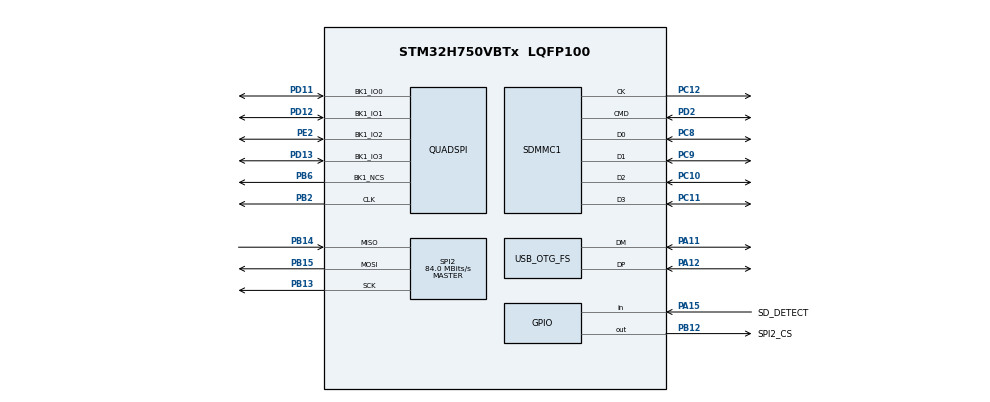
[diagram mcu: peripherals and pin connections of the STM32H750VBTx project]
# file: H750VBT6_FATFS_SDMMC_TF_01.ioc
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CORTEX_M7.AccessPermission-Cortex_Memory_Protection_Unit_Region0_Settings=MPU_REGION_FULL_ACCESS
CORTEX_M7.AccessPermission-Cortex_Memory_Protection_Unit_Region1_Settings=MPU_REGION_FULL_ACCESS
CORTEX_M7.AccessPermission-Cortex_Memory_Protection_Unit_Region2_Settings=MPU_REGION_FULL_ACCESS
CORTEX_M7.AccessPermission-Cortex_Memory_Protection_Unit_Region3_Settings=MPU_REGION_FULL_ACCESS
CORTEX_M7.AccessPermission-Cortex_Memory_Protection_Unit_Region4_Settings=MPU_REGION_FULL_ACCESS
CORTEX_M7.AccessPermission-Cortex_Memory_Protection_Unit_Region5_Settings=MPU_REGION_FULL_ACCESS
CORTEX_M7.AccessPermission-Cortex_Memory_Protection_Unit_Region6_Settings=MPU_REGION_FULL_ACCESS
CORTEX_M7.BaseAddress-Cortex_Memory_Protection_Unit_Region0_Settings=0x24000000
CORTEX_M7.BaseAddress-Cortex_Memory_Protection_Unit_Region1_Settings=0x60000000
CORTEX_M7.BaseAddress-Cortex_Memory_Protection_Unit_Region2_Settings=0x30000000
CORTEX_M7.BaseAddress-Cortex_Memory_Protection_Unit_Region3_Settings=0x30020000
CORTEX_M7.BaseAddress-Cortex_Memory_Protection_Unit_Region4_Settings=0x30040000
CORTEX_M7.BaseAddress-Cortex_Memory_Protection_Unit_Region5_Settings=0x38000000
CORTEX_M7.BaseAddress-Cortex_Memory_Protection_Unit_Region6_Settings=0x90000000
CORTEX_M7.CPU_DCache=Enabled
CORTEX_M7.CPU_ICache=Enabled
CORTEX_M7.Enable-Cortex_Memory_Protection_Unit_Region0_Settings=MPU_REGION_ENABLE
CORTEX_M7.Enable-Cortex_Memory_Protection_Unit_Region1_Settings=MPU_REGION_ENABLE
CORTEX_M7.Enable-Cortex_Memory_Protection_Unit_Region2_Settings=MPU_REGION_ENABLE
CORTEX_M7.Enable-Cortex_Memory_Protection_Unit_Region3_Settings=MPU_REGION_ENABLE
CORTEX_M7.Enable-Cortex_Memory_Protection_Unit_Region4_Settings=MPU_REGION_ENABLE
CORTEX_M7.Enable-Cortex_Memory_Protection_Unit_Region5_Settings=MPU_REGION_ENABLE
CORTEX_M7.Enable-Cortex_Memory_Protection_Unit_Region6_Settings=MPU_REGION_ENABLE
CORTEX_M7.IsBufferable-Cortex_Memory_Protection_Unit_Region0_Settings=MPU_ACCESS_BUFFERABLE
CORTEX_M7.IsBufferable-Cortex_Memory_Protection_Unit_Region1_Settings=MPU_ACCESS_BUFFERABLE
CORTEX_M7.IsBufferable-Cortex_Memory_Protection_Unit_Region6_Settings=MPU_ACCESS_BUFFERABLE
CORTEX_M7.IsCacheable-Cortex_Memory_Protection_Unit_Region0_Settings=MPU_ACCESS_CACHEABLE
CORTEX_M7.IsCacheable-Cortex_Memory_Protection_Unit_Region2_Settings=MPU_ACCESS_NOT_CACHEABLE
CORTEX_M7.IsCacheable-Cortex_Memory_Protection_Unit_Region3_Settings=MPU_ACCESS_NOT_CACHEABLE
CORTEX_M7.IsCacheable-Cortex_Memory_Protection_Unit_Region4_Settings=MPU_ACCESS_NOT_CACHEABLE
CORTEX_M7.IsCacheable-Cortex_Memory_Protection_Unit_Region5_Settings=MPU_ACCESS_CACHEABLE
CORTEX_M7.IsCacheable-Cortex_Memory_Protection_Unit_Region6_Settings=MPU_ACCESS_CACHEABLE
CORTEX_M7.MPU_Control=MPU_PRIVILEGED_DEFAULT
CORTEX_M7.Size-Cortex_Memory_Protection_Unit_Region0_Settings=MPU_REGION_SIZE_512KB
CORTEX_M7.Size-Cortex_Memory_Protection_Unit_Region1_Settings=MPU_REGION_SIZE_256MB
CORTEX_M7.Size-Cortex_Memory_Protection_Unit_Region2_Settings=MPU_REGION_SIZE_128KB
CORTEX_M7.Size-Cortex_Memory_Protection_Unit_Region3_Settings=MPU_REGION_SIZE_128KB
CORTEX_M7.Size-Cortex_Memory_Protection_Unit_Region4_Settings=MPU_REGION_SIZE_32KB
CORTEX_M7.Size-Cortex_Memory_Protection_Unit_Region5_Settings=MPU_REGION_SIZE_64KB
CORTEX_M7.Size-Cortex_Memory_Protection_Unit_Region6_Settings=MPU_REGION_SIZE_8MB
CORTEX_M7.TypeExtField-Cortex_Memory_Protection_Unit_Region0_Settings=MPU_TEX_LEVEL1
CORTEX_M7.TypeExtField-Cortex_Memory_Protection_Unit_Region6_Settings=MPU_TEX_LEVEL1
Dma.Request0=SPI2_RX
Dma.Request1=SPI2_TX
Dma.SPI2_RX.0.Direction=DMA_PERIPH_TO_MEMORY
Dma.SPI2_RX.0.EventEnable=DISABLE
Dma.SPI2_RX.0.FIFOMode=DMA_FIFOMODE_DISABLE
Dma.SPI2_RX.0.Instance=DMA1_Stream0
Dma.SPI2_RX.0.MemDataAlignment=DMA_MDATAALIGN_BYTE
Dma.SPI2_RX.0.MemInc=DMA_MINC_ENABLE
Dma.SPI2_RX.0.Mode=DMA_NORMAL
Dma.SPI2_RX.0.PeriphDataAlignment=DMA_PDATAALIGN_BYTE
Dma.SPI2_RX.0.PeriphInc=DMA_PINC_DISABLE
Dma.SPI2_RX.0.Polarity=HAL_DMAMUX_REQ_GEN_RISING
Dma.SPI2_RX.0.Priority=DMA_PRIORITY_VERY_HIGH
Dma.SPI2_RX.0.RequestNumber=1
Dma.SPI2_RX.0.SignalID=NONE
Dma.SPI2_RX.0.SyncEnable=DISABLE
Dma.SPI2_RX.0.SyncPolarity=HAL_DMAMUX_SYNC_NO_EVENT
Dma.SPI2_RX.0.SyncRequestNumber=1
Dma.SPI2_RX.0.SyncSignalID=NONE
Dma.SPI2_TX.1.Direction=DMA_MEMORY_TO_PERIPH
Dma.SPI2_TX.1.EventEnable=DISABLE
Dma.SPI2_TX.1.FIFOMode=DMA_FIFOMODE_DISABLE
Dma.SPI2_TX.1.Instance=DMA1_Stream1
Dma.SPI2_TX.1.MemDataAlignment=DMA_MDATAALIGN_BYTE
Dma.SPI2_TX.1.MemInc=DMA_MINC_ENABLE
Dma.SPI2_TX.1.Mode=DMA_NORMAL
Dma.SPI2_TX.1.PeriphDataAlignment=DMA_PDATAALIGN_BYTE
Dma.SPI2_TX.1.PeriphInc=DMA_PINC_DISABLE
Dma.SPI2_TX.1.Polarity=HAL_DMAMUX_REQ_GEN_RISING
Dma.SPI2_TX.1.Priority=DMA_PRIORITY_VERY_HIGH
Dma.SPI2_TX.1.RequestNumber=1
Dma.SPI2_TX.1.SignalID=NONE
Dma.SPI2_TX.1.SyncEnable=DISABLE
Dma.SPI2_TX.1.SyncPolarity=HAL_DMAMUX_SYNC_NO_EVENT
Dma.SPI2_TX.1.SyncRequestNumber=1
Dma.SPI2_TX.1.SyncSignalID=NONE
FATFS.BSP.number=1
FATFS._CODE_PAGE=936
FATFS._USE_LFN=2
FATFS._USE_MUTEX=0
FATFS0.BSP.STBoard=false
FATFS0.BSP.api=Unknown
FATFS0.BSP.instance=PA15 (JTDI)
FATFS0.BSP.ip=GPIO
FATFS0.BSP.mode=Input
FATFS0.BSP.name=Detect_SDIO
FATFS0.BSP.solution=PA15 (JTDI)
FREERTOS.INCLUDE_vTaskDelayUntil=1
FREERTOS.Tasks01=defaultTask,24,512,StartDefaultTask,Default,NULL,Dynamic,NULL,NULL
FREERTOS.configGENERATE_RUN_TIME_STATS=1
FREERTOS.configMAX_TASK_NAME_LEN=32
FREERTOS.configTOTAL_HEAP_SIZE=131072
FREERTOS.configUSE_NEWLIB_REENTRANT=1
FREERTOS.configUSE_STATS_FORMATTING_FUNCTIONS=1
FREERTOS.copyHeapFile=0
Mcu.Family=STM32H7
Mcu.Name=STM32H750VBTx
Mcu.Package=LQFP100
Mcu.UserConstants=QSPI_FLASH_SIZE_2N_OFFSET,0
NVIC.DMA1_Stream0_IRQn=true\:5\:0\:false\:false\:true\:true\:false\:true\:true
NVIC.DMA1_Stream1_IRQn=true\:5\:0\:false\:false\:true\:true\:false\:true\:true
NVIC.OTG_FS_IRQn=true\:5\:0\:false\:false\:true\:true\:false\:true\:true
NVIC.PriorityGroup=NVIC_PRIORITYGROUP_4
NVIC.SDMMC1_IRQn=true\:5\:0\:false\:false\:true\:true\:true\:true\:true
NVIC.SPI2_IRQn=true\:5\:0\:false\:false\:true\:true\:false\:true\:true
NVIC.TIM3_IRQn=true\:14\:0\:true\:false\:true\:true\:true\:true\:true
NVIC.TIM6_DAC_IRQn=true\:15\:0\:true\:false\:true\:false\:true\:true\:true
NVIC.TIM7_IRQn=true\:0\:0\:true\:false\:true\:false\:true\:true\:true
NVIC.TimeBase=TIM6_DAC_IRQn
NVIC.TimeBaseIP=TIM6
PA11.GPIO_Speed=GPIO_SPEED_FREQ_VERY_HIGH
PA11.Mode=Device_Only
PA11.Signal=USB_OTG_FS_DM
PA12.GPIO_Speed=GPIO_SPEED_FREQ_VERY_HIGH
PA12.Mode=Device_Only
PA12.Signal=USB_OTG_FS_DP
PA13\ (JTMS/SWDIO).Mode=Serial_Wire
PA13\ (JTMS/SWDIO).Signal=DEBUG_JTMS-SWDIO
PA14\ (JTCK/SWCLK).Mode=Serial_Wire
PA14\ (JTCK/SWCLK).Signal=DEBUG_JTCK-SWCLK
PA15\ (JTDI).GPIO_Label=SD_DETECT
PA15\ (JTDI).Signal=GPIO_Input
PB12.GPIO_Label=SPI2_CS
PB12.GPIO_ModeDefaultOutputPP=GPIO_MODE_OUTPUT_OD
PB12.GPIO_PuPd=GPIO_NOPULL
PB12.GPIO_Speed=GPIO_SPEED_FREQ_VERY_HIGH
PB12.PinState=GPIO_PIN_SET
PB12.Signal=GPIO_Output
PB13.GPIO_Speed=GPIO_SPEED_FREQ_VERY_HIGH
PB13.Mode=Full_Duplex_Master
PB13.Signal=SPI2_SCK
PB14.GPIO_Speed=GPIO_SPEED_FREQ_VERY_HIGH
PB14.Mode=Full_Duplex_Master
PB14.Signal=SPI2_MISO
PB15.GPIO_Speed=GPIO_SPEED_FREQ_VERY_HIGH
PB15.Mode=Full_Duplex_Master
PB15.Signal=SPI2_MOSI
PB2.Mode=Single Bank 1
PB2.Signal=QUADSPI_CLK
PB6.Mode=Single Bank 1
PB6.Signal=QUADSPI_BK1_NCS
PC10.Mode=SD_4_bits_Wide_bus
PC10.Signal=SDMMC1_D2
PC11.Mode=SD_4_bits_Wide_bus
PC11.Signal=SDMMC1_D3
PC12.Mode=SD_4_bits_Wide_bus
PC12.Signal=SDMMC1_CK
PC8.Mode=SD_4_bits_Wide_bus
PC8.Signal=SDMMC1_D0
PC9.Mode=SD_4_bits_Wide_bus
PC9.Signal=SDMMC1_D1
PD11.Mode=Single Bank 1
PD11.Signal=QUADSPI_BK1_IO0
PD12.Mode=Single Bank 1
PD12.Signal=QUADSPI_BK1_IO1
PD13.Mode=Single Bank 1
PD13.Signal=QUADSPI_BK1_IO3
PD2.Mode=SD_4_bits_Wide_bus
PD2.Signal=SDMMC1_CMD
PE2.Mode=Single Bank 1
PE2.Signal=QUADSPI_BK1_IO2
PH0-OSC_IN\ (PH0).Mode=HSE-External-Oscillator
PH0-OSC_IN\ (PH0).Signal=RCC_OSC_IN
PH1-OSC_OUT\ (PH1).Mode=HSE-External-Oscillator
PH1-OSC_OUT\ (PH1).Signal=RCC_OSC_OUT
ProjectManager.HeapSize=0x1000
ProjectManager.StackSize=0x1000
ProjectManager.TargetToolchain=STM32CubeIDE
QUADSPI.ChipSelectHighTime=QSPI_CS_HIGH_TIME_2_CYCLE
QUADSPI.ClockPrescaler=1
QUADSPI.FifoThreshold=32
QUADSPI.FlashSize=QSPI_FLASH_SIZE_2N_OFFSET
QUADSPI.SampleShifting=QSPI_SAMPLE_SHIFTING_HALFCYCLE
RCC.ADCFreq_Value=168000000
RCC.APB1Freq_Value=100000000
RCC.APB2Freq_Value=100000000
RCC.APB3Freq_Value=100000000
RCC.APB4Freq_Value=100000000
RCC.CECCLockSelection=RCC_CECCLKSOURCE_LSI
RCC.CKPERSourceSelection=RCC_CLKPSOURCE_HSE
RCC.CSI_VALUE=4000000
RCC.CortexFreq_Value=400000000
RCC.Cortex_Div=SYSTICK_CLKSOURCE_HCLK
RCC.Cortex_DivARG=SystemCoreClock/1000
RCC.D1PPRE=RCC_APB3_DIV2
RCC.D2PPRE1=RCC_APB1_DIV2
RCC.D2PPRE2=RCC_APB2_DIV2
RCC.D3PPRE=RCC_APB4_DIV2
RCC.DFSDMCLockSelection=RCC_DFSDM1CLKSOURCE_D2PCLK1
RCC.DIVM1=5
RCC.DIVM2=25
RCC.DIVM3=25
RCC.DIVN1=160
RCC.DIVN2=504
RCC.DIVN3=160
RCC.DIVP1=2
RCC.DIVP2=3
RCC.DIVP3=2
RCC.DIVQ1=4
RCC.DIVQ2=2
RCC.DIVR1=2
RCC.DIVR2=2
RCC.DIVR3=25
RCC.DSICLockSelection=RCC_DSICLKSOURCE_PHY
RCC.DSIPHY_Div=8
RCC.DSITX_Div=4
RCC.DSI_PHY_VALUE=12288000
RCC.EXTERNAL_CLOCK_VALUE=12288000
RCC.FDCANCLockSelection=RCC_FDCANCLKSOURCE_PLL
RCC.FMCCLockSelection=RCC_FMCCLKSOURCE_D1HCLK
RCC.HCLKFreq_Value=200000000
RCC.HPRE=RCC_HCLK_DIV2
RCC.HSE_VALUE=25000000
RCC.HSIDiv=RCC_PLLSAIDIVR_1
RCC.HSI_VALUE=64000000
RCC.I2C123CLockSelection=RCC_I2C123CLKSOURCE_D2PCLK1
RCC.I2C4CLockSelection=RCC_I2C4CLKSOURCE_D3PCLK1
RCC.LPTIM1CLockSelection=RCC_LPTIM1CLKSOURCE_PLL3
RCC.LPTIM2CLockSelection=RCC_LPTIM2CLKSOURCE_D3PCLK1
RCC.LPTIM345CLockSelection=RCC_LPTIM345CLKSOURCE_PLL3
RCC.LPUART1CLockSelection=RCC_LPUART1CLKSOURCE_D3PCLK1
RCC.PLL1_VCI_Range-AdvancedSettings=RCC_PLL1VCIRANGE_0
RCC.PLL1_VCO_SEL-AdvancedSettings=RCC_PLL1VCOWIDE
RCC.PLLDSIDev=2
RCC.PLLDSIIDF=DSI_PLL_IN_DIV1
RCC.PLLDSIMult=2
RCC.PLLDSINDIV=20
RCC.PLLDSIODF=DSI_PLL_OUT_DIV1
RCC.PLLSourceVirtual=RCC_PLLSOURCE_HSE
RCC.RC48_VALUE=48000000
RCC.RCC_MCO1Source=RCC_MCO1SOURCE_HSI
RCC.RCC_MCO2Source=RCC_MCO2SOURCE_SYSCLK
RCC.RCC_MCODiv1=RCC_MCODIV_1
RCC.RCC_MCODiv2=RCC_MCODIV_1
RCC.RCC_RTC_Clock_Source_FROM_HSE=RCC_RTCCLKSOURCE_HSE_DIV2
RCC.RNGCLockSelection=RCC_RNGCLKSOURCE_HSI48
RCC.SAI1CLockSelection=RCC_SAI1CLKSOURCE_PLL
RCC.SAI23CLockSelection=RCC_SAI23CLKSOURCE_PLL
RCC.SAI4ACLockSelection=RCC_SAI4ACLKSOURCE_PLL
RCC.SAI4BCLockSelection=RCC_SAI4BCLKSOURCE_PLL
RCC.SPDIFCLockSelection=RCC_SPDIFRXCLKSOURCE_PLL
RCC.SPI123CLockSelection=RCC_SPI123CLKSOURCE_PLL2
RCC.SPI6CLockSelection=RCC_SPI6CLKSOURCE_D3PCLK1
RCC.SWPCLockSelection=RCC_SWPMI1CLKSOURCE_D2PCLK1
RCC.SYSCLKFreq_VALUE=400000000
RCC.SYSCLKSource=RCC_SYSCLKSOURCE_PLLCLK
RCC.Spi45ClockSelection=RCC_SPI45CLKSOURCE_D2PCLK1
RCC.USART16CLockSelection=RCC_USART16CLKSOURCE_D2PCLK2
RCC.USART234578CLockSelection=RCC_USART234578CLKSOURCE_D2PCLK1
RCC.USBCLockSelection=RCC_USBCLKSOURCE_HSI48
RCC.USBFreq_Value=48000000
SDMMC1.ClockDiv=4
SPI2.BaudRatePrescaler=SPI_BAUDRATEPRESCALER_2
SPI2.CalculateBaudRate=84.0 MBits/s
SPI2.DataSize=SPI_DATASIZE_8BIT
SPI2.Direction=SPI_DIRECTION_2LINES
SPI2.Mode=SPI_MODE_MASTER
SPI2.VirtualType=VM_MASTER
TIM3.AutoReloadPreload=TIM_AUTORELOAD_PRELOAD_ENABLE
TIM3.Channel-Output\ Compare1\ No\ Output=TIM_CHANNEL_1
TIM3.Channel-Output\ Compare2\ No\ Output=TIM_CHANNEL_2
TIM3.Channel-Output\ Compare3\ No\ Output=TIM_CHANNEL_3
TIM3.Channel-Output\ Compare4\ No\ Output=TIM_CHANNEL_4
TIM3.OC1Preload=DISABLE
TIM3.OCMode_1=TIM_OCMODE_TOGGLE
TIM3.OCMode_2=TIM_OCMODE_TIMING
TIM3.OCMode_3=TIM_OCMODE_TIMING
TIM3.OCMode_4=TIM_OCMODE_TIMING
TIM7.AutoReloadPreload=TIM_AUTORELOAD_PRELOAD_DISABLE
TIM7.Period=50- 1
TIM7.Prescaler=200 - 1
USB_DEVICE.APP_RX_DATA_SIZE-CDC_FS=2048
USB_DEVICE.APP_TX_DATA_SIZE-CDC_FS=2048
USB_DEVICE.CLASS_NAME_FS=CDC
USB_DEVICE.VirtualMode-CDC_FS=Cdc
USB_DEVICE.VirtualModeFS=Cdc_FS
USB_OTG_FS.VirtualMode=Device_Only
VP_FATFS_VS_SDIO.Mode=SDIO
VP_FREERTOS_VS_CMSIS_V2.Mode=CMSIS_V2
VP_SYS_VS_tim6.Mode=TIM6
VP_TIM3_VS_no_output1.Mode=Output Compare1 No Output
VP_TIM3_VS_no_output2.Mode=Output Compare2 No Output
VP_TIM3_VS_no_output3.Mode=Output Compare3 No Output
VP_TIM3_VS_no_output4.Mode=Output Compare4 No Output
VP_TIM7_VS_ClockSourceINT.Mode=Enable_Timer
VP_USB_DEVICE_VS_USB_DEVICE_CDC_FS.Mode=CDC_FS
board=custom

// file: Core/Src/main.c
/* USER CODE BEGIN Header */
/**
  ******************************************************************************
  * @file           : main.c
  * @brief          : Main program body
  ******************************************************************************
  * @attention
  *
  * <h2><center>&copy; Copyright (c) 2022 STMicroelectronics.
  * All rights reserved.</center></h2>
  *
  * This software component is licensed by ST under BSD 3-Clause license,
  * the "License"; You may not use this file except in compliance with the
  * License. You may obtain a copy of the License at:
  *                        opensource.org/licenses/BSD-3-Clause
  *
  ******************************************************************************
  */
/* USER CODE END Header */
#include "main.h"
#include "cmsis_os.h"
#include "dma.h"
#include "fatfs.h"
#include "sdmmc.h"
#include "spi.h"
#include "tim.h"
#include "usb_device.h"
#include "gpio.h"

/* USER CODE BEGIN Includes */
#include "usbd_cdc_if.h"
/* USER CODE END Includes */

void SystemClock_Config(void);
static void MPU_Config(void);
void MX_FREERTOS_Init(void);

int main(void)
{
  /* USER CODE BEGIN 1 */
//	SCB->VTOR = 0x90000000; /* 设置中断向量表Addr */
  /* USER CODE END 1 */

  /* MPU Configuration--------------------------------------------------------*/
  MPU_Config();

  /* Enable I-Cache---------------------------------------------------------*/
  SCB_EnableICache();

  /* Enable D-Cache---------------------------------------------------------*/
  SCB_EnableDCache();

  /* MCU Configuration--------------------------------------------------------*/

  /* Reset of all peripherals, Initializes the Flash interface and the Systick. */
  HAL_Init();

  /* USER CODE BEGIN Init */
  USB_Status_Init();
  /* USER CODE END Init */

  /* Configure the system clock */
  SystemClock_Config();

  /* Initialize all configured peripherals */
  MX_GPIO_Init();
  MX_DMA_Init();
  MX_TIM3_Init();
  MX_TIM7_Init();
  MX_SPI2_Init();
  MX_SDMMC1_SD_Init();
  MX_FATFS_Init();

  /* Init scheduler */
  osKernelInitialize();  /* Call init function for freertos objects (in freertos.c) */
  MX_FREERTOS_Init();

  /* Start scheduler */
  osKernelStart();

  /* We should never get here as control is now taken by the scheduler */
  /* Infinite loop */
  while (1)
  {

  }
}

void SystemClock_Config(void)
{
  RCC_OscInitTypeDef RCC_OscInitStruct = {0};
  RCC_ClkInitTypeDef RCC_ClkInitStruct = {0};

  /** Supply configuration update enable
  */
  HAL_PWREx_ConfigSupply(PWR_LDO_SUPPLY);

  /** Configure the main internal regulator output voltage
  */
  __HAL_PWR_VOLTAGESCALING_CONFIG(PWR_REGULATOR_VOLTAGE_SCALE1);

  while(!__HAL_PWR_GET_FLAG(PWR_FLAG_VOSRDY)) {}

  /** Macro to configure the PLL clock source
  */
  __HAL_RCC_PLL_PLLSOURCE_CONFIG(RCC_PLLSOURCE_HSE);

  /** Initializes the RCC Oscillators according to the specified parameters
  * in the RCC_OscInitTypeDef structure.
  */
  RCC_OscInitStruct.OscillatorType = RCC_OSCILLATORTYPE_HSI48|RCC_OSCILLATORTYPE_HSE;
  RCC_OscInitStruct.HSEState = RCC_HSE_ON;
  RCC_OscInitStruct.HSI48State = RCC_HSI48_ON;
  RCC_OscInitStruct.PLL.PLLState = RCC_PLL_ON;
  RCC_OscInitStruct.PLL.PLLSource = RCC_PLLSOURCE_HSE;
  RCC_OscInitStruct.PLL.PLLM = 5;
  RCC_OscInitStruct.PLL.PLLN = 160;
  RCC_OscInitStruct.PLL.PLLP = 2;
  RCC_OscInitStruct.PLL.PLLQ = 4;
  RCC_OscInitStruct.PLL.PLLR = 2;
  RCC_OscInitStruct.PLL.PLLRGE = RCC_PLL1VCIRANGE_2;
  RCC_OscInitStruct.PLL.PLLVCOSEL = RCC_PLL1VCOWIDE;
  RCC_OscInitStruct.PLL.PLLFRACN = 0;
  if (HAL_RCC_OscConfig(&RCC_OscInitStruct) != HAL_OK)
  {
    Error_Handler();
  }

  /** Initializes the CPU, AHB and APB buses clocks
  */
  RCC_ClkInitStruct.ClockType = RCC_CLOCKTYPE_HCLK|RCC_CLOCKTYPE_SYSCLK
                              |RCC_CLOCKTYPE_PCLK1|RCC_CLOCKTYPE_PCLK2
                              |RCC_CLOCKTYPE_D3PCLK1|RCC_CLOCKTYPE_D1PCLK1;
  RCC_ClkInitStruct.SYSCLKSource = RCC_SYSCLKSOURCE_PLLCLK;
  RCC_ClkInitStruct.SYSCLKDivider = RCC_SYSCLK_DIV1;
  RCC_ClkInitStruct.AHBCLKDivider = RCC_HCLK_DIV2;
  RCC_ClkInitStruct.APB3CLKDivider = RCC_APB3_DIV2;
  RCC_ClkInitStruct.APB1CLKDivider = RCC_APB1_DIV2;
  RCC_ClkInitStruct.APB2CLKDivider = RCC_APB2_DIV2;
  RCC_ClkInitStruct.APB4CLKDivider = RCC_APB4_DIV2;

  if (HAL_RCC_ClockConfig(&RCC_ClkInitStruct, FLASH_LATENCY_2) != HAL_OK)
  {
    Error_Handler();
  }
}

/* USER CODE BEGIN 4 */
volatile uint8_t tim17_transmissionReceived = 0;
volatile uint32_t ulHighFrequencyTimerTicks = 0UL;  /* FreeRTOS variables for statistical CPU utilization */

void configureTimerForRunTimeStats(void) {
	ulHighFrequencyTimerTicks = 0UL;
}

unsigned long getRunTimeCounterValue(void) {
	return ulHighFrequencyTimerTicks;
}

void _Error_Handler(const char * file, uint32_t line)
{
  /* USER CODE BEGIN Error_Handler_Debug */
  /* User can add his own implementation to report the HAL error return state */
  __disable_irq();
  while (1)
  {
  }
  /* USER CODE END Error_Handler_Debug */
}
/* USER CODE END 4 */

/* MPU Configuration */

void MPU_Config(void)
{
  MPU_Region_InitTypeDef MPU_InitStruct = {0};

  /* Disables the MPU */
  HAL_MPU_Disable();

  /** Initializes and configures the Region and the memory to be protected
  */
  MPU_InitStruct.Enable = MPU_REGION_ENABLE;
  MPU_InitStruct.Number = MPU_REGION_NUMBER0;
  MPU_InitStruct.BaseAddress = 0x24000000;
  MPU_InitStruct.Size = MPU_REGION_SIZE_512KB;
  MPU_InitStruct.SubRegionDisable = 0x0;
  MPU_InitStruct.TypeExtField = MPU_TEX_LEVEL1;
  MPU_InitStruct.AccessPermission = MPU_REGION_FULL_ACCESS;
  MPU_InitStruct.DisableExec = MPU_INSTRUCTION_ACCESS_ENABLE;
  MPU_InitStruct.IsShareable = MPU_ACCESS_NOT_SHAREABLE;
  MPU_InitStruct.IsCacheable = MPU_ACCESS_CACHEABLE;
  MPU_InitStruct.IsBufferable = MPU_ACCESS_BUFFERABLE;

  HAL_MPU_ConfigRegion(&MPU_InitStruct);

  /** Initializes and configures the Region and the memory to be protected
  */
  MPU_InitStruct.Number = MPU_REGION_NUMBER1;
  MPU_InitStruct.BaseAddress = 0x60000000;
  MPU_InitStruct.Size = MPU_REGION_SIZE_256MB;
  MPU_InitStruct.TypeExtField = MPU_TEX_LEVEL0;
  MPU_InitStruct.IsCacheable = MPU_ACCESS_NOT_CACHEABLE;

  HAL_MPU_ConfigRegion(&MPU_InitStruct);

  /** Initializes and configures the Region and the memory to be protected
  */
  MPU_InitStruct.Number = MPU_REGION_NUMBER2;
  MPU_InitStruct.BaseAddress = 0x30000000;
  MPU_InitStruct.Size = MPU_REGION_SIZE_128KB;
  MPU_InitStruct.IsBufferable = MPU_ACCESS_NOT_BUFFERABLE;

  HAL_MPU_ConfigRegion(&MPU_InitStruct);

  /** Initializes and configures the Region and the memory to be protected
  */
  MPU_InitStruct.Number = MPU_REGION_NUMBER3;
  MPU_InitStruct.BaseAddress = 0x30020000;

  HAL_MPU_ConfigRegion(&MPU_InitStruct);

  /** Initializes and configures the Region and the memory to be protected
  */
  MPU_InitStruct.Number = MPU_REGION_NUMBER4;
  MPU_InitStruct.BaseAddress = 0x30040000;
  MPU_InitStruct.Size = MPU_REGION_SIZE_32KB;

  HAL_MPU_ConfigRegion(&MPU_InitStruct);

  /** Initializes and configures the Region and the memory to be protected
  */
  MPU_InitStruct.Number = MPU_REGION_NUMBER5;
  MPU_InitStruct.BaseAddress = 0x38000000;
  MPU_InitStruct.Size = MPU_REGION_SIZE_64KB;
  MPU_InitStruct.IsCacheable = MPU_ACCESS_CACHEABLE;

  HAL_MPU_ConfigRegion(&MPU_InitStruct);

  /** Initializes and configures the Region and the memory to be protected
  */
  MPU_InitStruct.Number = MPU_REGION_NUMBER6;
  MPU_InitStruct.BaseAddress = 0x90000000;
  MPU_InitStruct.Size = MPU_REGION_SIZE_8MB;
  MPU_InitStruct.TypeExtField = MPU_TEX_LEVEL1;
  MPU_InitStruct.IsBufferable = MPU_ACCESS_BUFFERABLE;

  HAL_MPU_ConfigRegion(&MPU_InitStruct);
  /* Enables the MPU */
  HAL_MPU_Enable(MPU_PRIVILEGED_DEFAULT);

}

void HAL_TIM_PeriodElapsedCallback(TIM_HandleTypeDef *htim)
{
  /* USER CODE BEGIN Callback 0 */
	if(htim->Instance == TIM7) {
		ulHighFrequencyTimerTicks++;
	}
  /* USER CODE END Callback 0 */
  if (htim->Instance == TIM6) {
    HAL_IncTick();
  }
}

void Error_Handler(void)
{
  __disable_irq();
  while (1)
  {
  }
}
